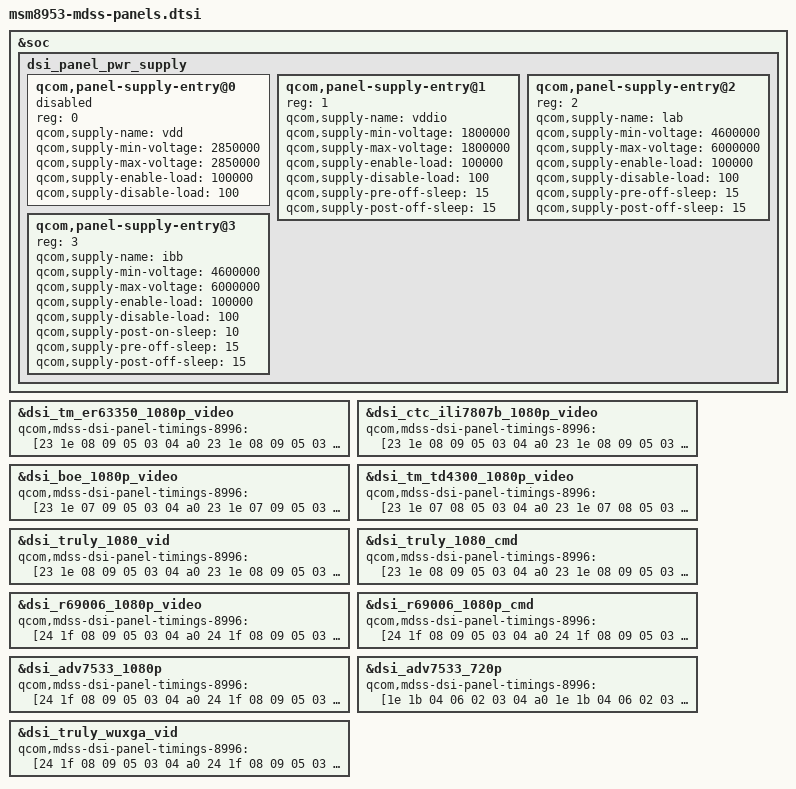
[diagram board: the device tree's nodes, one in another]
/* Copyright (c) 2015-2016, The Linux Foundation. All rights reserved.
 *
 * This program is free software; you can redistribute it and/or modify
 * it under the terms of the GNU General Public License version 2 and
 * only version 2 as published by the Free Software Foundation.
 *
 * This program is distributed in the hope that it will be useful,
 * but WITHOUT ANY WARRANTY; without even the implied warranty of
 * MERCHANTABILITY or FITNESS FOR A PARTICULAR PURPOSE.  See the
 * GNU General Public License for more details.
 */

#include "dsi-panel-sim-video.dtsi"
#include "dsi-panel-sim-dualmipi-video.dtsi"
#include "dsi-panel-sim-cmd.dtsi"
#include "dsi-panel-sim-dualmipi-cmd.dtsi"
#include "dsi-panel-truly-1080p-video.dtsi"
#include "dsi-panel-truly-1080p-cmd.dtsi"
#include "dsi-adv7533-1080p.dtsi"
#include "dsi-adv7533-720p.dtsi"
#include "dsi-panel-r69006-1080p-video.dtsi"
#include "dsi-panel-r69006-1080p-cmd.dtsi"
#include "dsi-panel-truly-wuxga-video.dtsi"
//<ASUS_Hank2_Liu_20160217 Bring up panel >++++++
#include "dsi-panel-tm-er63350-1080p-video.dtsi"
#include "dsi-panel-ctc-ili7807b-1080p-video.dtsi"
#include "dsi-panel-boe-1080p-video.dtsi"
#include "dsi-panel-tm-td4300-1080p-video.dtsi"
//<ASUS_Hank2_Liu_20160217 Bring up panel >-------

&soc {
	dsi_panel_pwr_supply: dsi_panel_pwr_supply {
		#address-cells = <1>;
		#size-cells = <0>;

		qcom,panel-supply-entry@0 {
			reg = <0>;
			status="disable";
			qcom,supply-name = "vdd";
			qcom,supply-min-voltage = <2850000>;
			qcom,supply-max-voltage = <2850000>;
			qcom,supply-enable-load = <100000>;
			qcom,supply-disable-load = <100>;
		};

		qcom,panel-supply-entry@1 {
			reg = <1>;
			qcom,supply-name = "vddio";
			qcom,supply-min-voltage = <1800000>;
			qcom,supply-max-voltage = <1800000>;
			qcom,supply-enable-load = <100000>;
			qcom,supply-disable-load = <100>;
			qcom,supply-pre-off-sleep = <15>;
			qcom,supply-post-off-sleep = <15>;
		};

		qcom,panel-supply-entry@2 {
			reg = <2>;
			qcom,supply-name = "lab";
			qcom,supply-min-voltage = <4600000>;
			qcom,supply-max-voltage = <6000000>;
			qcom,supply-enable-load = <100000>;
			qcom,supply-disable-load = <100>;
			qcom,supply-pre-off-sleep = <15>;
			qcom,supply-post-off-sleep = <15>;
		};

		qcom,panel-supply-entry@3 {
			reg = <3>;
			qcom,supply-name = "ibb";
			qcom,supply-min-voltage = <4600000>;
			qcom,supply-max-voltage = <6000000>;
			qcom,supply-enable-load = <100000>;
			qcom,supply-disable-load = <100>;
			qcom,supply-post-on-sleep = <10>;
			qcom,supply-pre-off-sleep = <15>;
			qcom,supply-post-off-sleep = <15>;
		};
	};
};

//<ASUS_Hank2_Liu_20160217 Bring up panel >++++++
&dsi_tm_er63350_1080p_video{
	qcom,mdss-dsi-panel-timings-8996 = [23 1e 08 09 05 03 04 a0
		23 1e 08 09 05 03 04 a0
		23 1e 08 09 05 03 04 a0
		23 1e 08 09 05 03 04 a0
		23 1a 08 09 05 03 04 a0];
};

&dsi_ctc_ili7807b_1080p_video{
	qcom,mdss-dsi-panel-timings-8996 = [23 1e 08 09 05 03 04 a0
		23 1e 08 09 05 03 04 a0
		23 1e 08 09 05 03 04 a0
		23 1e 08 09 05 03 04 a0
		23 1a 08 09 05 03 04 a0];
};

&dsi_boe_1080p_video{
	qcom,mdss-dsi-panel-timings-8996 = [23 1e 07 09 05 03 04 a0
		23 1e 07 09 05 03 04 a0
		23 1e 07 09 05 03 04 a0
		23 1e 07 09 05 03 04 a0
		23 19 07 08 05 03 04 a0];
};

&dsi_tm_td4300_1080p_video{
	qcom,mdss-dsi-panel-timings-8996 = [23 1e 07 08 05 03 04 a0
		23 1e 07 08 05 03 04 a0
		23 1e 07 08 05 03 04 a0
		23 1e 07 08 05 03 04 a0
		23 19 07 08 05 03 04 a0];
};
//<ASUS_Hank2_Liu_20160217 Bring up panel >------

&dsi_truly_1080_vid {
	qcom,mdss-dsi-panel-timings-8996 = [23 1e 08 09 05 03 04 a0
		23 1e 08 09 05 03 04 a0
		23 1e 08 09 05 03 04 a0
		23 1e 08 09 05 03 04 a0
		23 1a 08 09 05 03 04 a0];
};

&dsi_truly_1080_cmd {
	qcom,mdss-dsi-panel-timings-8996 = [23 1e 08 09 05 03 04 a0
		23 1e 08 09 05 03 04 a0
		23 1e 08 09 05 03 04 a0
		23 1e 08 09 05 03 04 a0
		23 1a 08 09 05 03 04 a0];
};

&dsi_r69006_1080p_video {
	qcom,mdss-dsi-panel-timings-8996 = [24 1f 08 09 05 03 04 a0
		24 1f 08 09 05 03 04 a0
		24 1f 08 09 05 03 04 a0
		24 1f 08 09 05 03 04 a0
		24 1b 08 09 05 03 04 a0];
};

&dsi_r69006_1080p_cmd{
	qcom,mdss-dsi-panel-timings-8996 = [24 1f 08 09 05 03 04 a0
		24 1f 08 09 05 03 04 a0
		24 1f 08 09 05 03 04 a0
		24 1f 08 09 05 03 04 a0
		24 1b 08 09 05 03 04 a0];
};

&dsi_adv7533_1080p {
	qcom,mdss-dsi-panel-timings-8996 = [24 1f 08 09 05 03 04 a0
		24 1f 08 09 05 03 04 a0
		24 1f 08 09 05 03 04 a0
		24 1f 08 09 05 03 04 a0
		24 1b 08 09 05 03 04 a0];
};

&dsi_adv7533_720p {
	qcom,mdss-dsi-panel-timings-8996 = [1e 1b 04 06 02 03 04 a0
		1e 1b 04 06 02 03 04 a0
		1e 1b 04 06 02 03 04 a0
		1e 1b 04 06 02 03 04 a0
		1e 0e 04 05 02 03 04 a0];
};

&dsi_truly_wuxga_vid {
	qcom,mdss-dsi-panel-timings-8996 = [24 1f 08 09 05 03 04 a0
		24 1f 08 09 05 03 04 a0
		24 1f 08 09 05 03 04 a0
		24 1f 08 09 05 03 04 a0
		24 1c 08 09 05 03 04 a0];
};
